# STM32H7P4xx register map
File version: 1.0
Registers are 32-bit, read-write, reset 0x0 unless marked. A register's access mark holds for its fields unless they carry their own. Offsets are from the block's base; [hi:lo] are bit positions.

## FDCAN1 — FD Controller Area Network (FDCAN)
Base 0x4000A000
Same registers: FDCAN2 0x4000A400, FDCAN3 0x4000A800
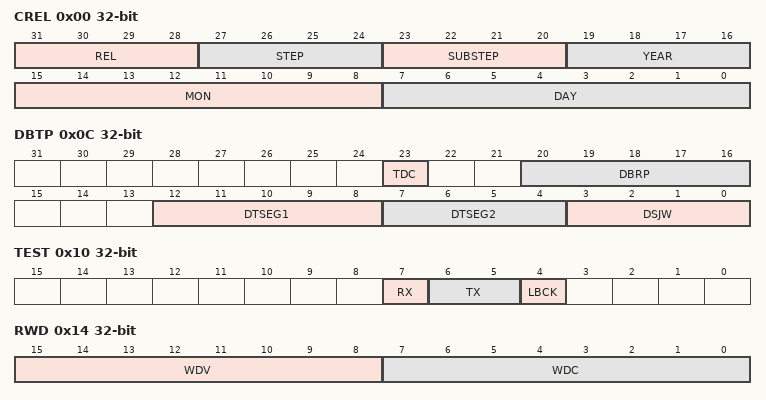
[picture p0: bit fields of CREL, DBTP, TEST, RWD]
0x00 CREL ro — FDCAN Core Release register
  [31:28] REL, [27:24] STEP, [23:20] SUBSTEP, [19:16] YEAR, [15:8] MON, [7:0] DAY
0x04 ENDN ro — FDCAN Endian register
  [31:0] ETV — Endianness test value
0x0C DBTP — FDCAN Data Bit Timing & Prescaler register
  [23] TDC — Transceiver delay compensation
  [20:16] DBRP — Data bit rate prescaler
  [12:8] DTSEG1 — Data time segment before sample point
  [7:4] DTSEG2 — Data time segment after sample point
  [3:0] DSJW — Synchronization jump width
0x10 TEST — FDCAN Test register
  [7] RX — Receive pin
  [6:5] TX — Control of transmit pin
  [4] LBCK — Loop back mode
0x14 RWD — FDCAN RAM Watchdog register
  [15:8] WDV — Watchdog value
  [7:0] WDC — Watchdog configuration
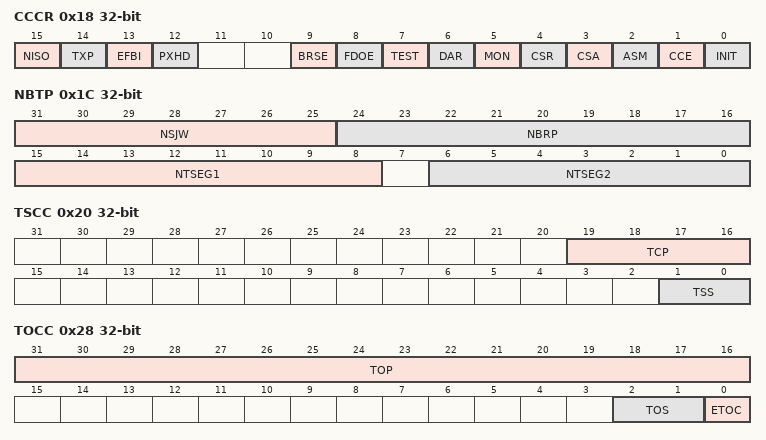
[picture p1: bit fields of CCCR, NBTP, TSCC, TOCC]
0x18 CCCR — FDCAN CC Control register
  [15] NISO — Non ISO operation
  [14] TXP — If this bit is set, the FDCAN pauses for two CAN bit times before starting the next transmission after successfully transmitting a frame
  [13] EFBI — Edge filtering during bus integration
  [12] PXHD — Protocol exception handling disable
  [9] BRSE — FDCAN bit rate switching
  [8] FDOE — FD operation enable
  [7] TEST — Test mode enable
  [6] DAR — Disable automatic retransmission
  [5] MON — Bus monitoring mode
  [4] CSR — Clock stop request
  [3] CSA — Clock stop acknowledge
  [2] ASM — ASM restricted operation mode
  [1] CCE — Configuration change enable
  [0] INIT — Initialization
0x1C NBTP — FDCAN Nominal Bit Timing & Prescaler register
  [31:25] NSJW — Nominal (re)synchronization jump width
  [24:16] NBRP — Bit rate prescaler
  [15:8] NTSEG1 — Nominal time segment before sample point
  [6:0] NTSEG2 — Nominal time segment after sample point
0x20 TSCC — FDCAN Timestamp Counter Configuration register
  [19:16] TCP — Timestamp counter prescaler
  [1:0] TSS — Timestamp select
0x24 TSCV — FDCAN Timestamp Counter Value register
  [15:0] TSC — Timestamp counter
0x28 TOCC — FDCAN Timeout Counter Configuration register
  [31:16] TOP — Timeout period
  [2:1] TOS — Timeout select
  [0] ETOC — Timeout counter enable
0x2C TOCV — FDCAN Timeout Counter Value register
  [15:0] TOC — Timeout counter
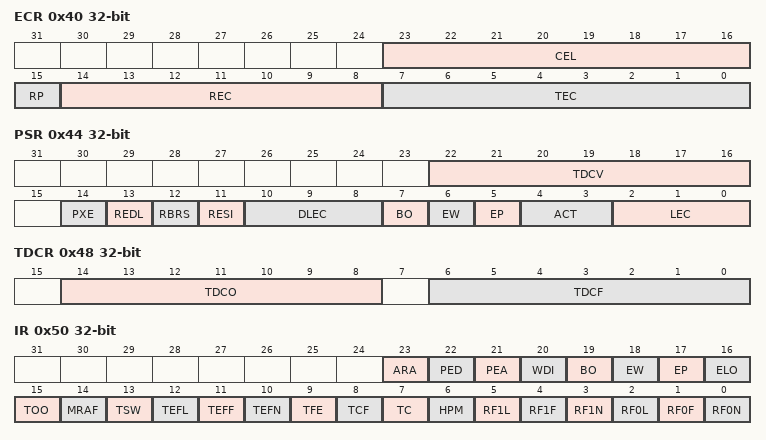
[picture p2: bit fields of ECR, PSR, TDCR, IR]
0x40 ECR ro — FDCAN Error Counter register
  [23:16] CEL — CAN error logging
  [15] RP — Receive error passive
  [14:8] REC — Receive error counter
  [7:0] TEC — Transmit error counter
0x44 PSR ro — FDCAN Protocol Status register
  [22:16] TDCV — Transmitter delay compensation value
  [14] PXE — Protocol exception event
  [13] REDL — Received FDCAN message
  [12] RBRS — BRS flag of last received FDCAN message
  [11] RESI — ESI flag of last received FDCAN message
  [10:8] DLEC — Data last error code
  [7] BO — Bus_Off status
  [6] EW — Warning Sstatus
  [5] EP — Error passive
  [4:3] ACT — Activity
  [2:0] LEC — Last error code
0x48 TDCR — FDCAN Transmitter Delay Compensation register
  [14:8] TDCO — Transmitter delay compensation offset
  [6:0] TDCF — Transmitter delay compensation filter window length
0x50 IR — FDCAN Interrupt register
  [23] ARA — Access to reserved address
  [22] PED — Protocol error in data phase (data bit time is used)
  [21] PEA — Protocol error in arbitration phase (nominal bit time is used)
  [20] WDI — Watchdog interrupt
  [19] BO — Bus_Off status
  [18] EW — Warning status
  [17] EP — Error passive
  [16] ELO — Error logging overflow
  [15] TOO — Timeout occurred
  [14] MRAF — Message RAM access failure
  [13] TSW — Timestamp wraparound
  [12] TEFL — Tx event FIFO element lost
  [11] TEFF — Tx event FIFO full
  [10] TEFN — Tx event FIFO New Entry
  [9] TFE — Tx FIFO empty
  [8] TCF — Transmission cancellation finished
  [7] TC — Transmission completed
  [6] HPM — High-priority message
  [5] RF1L — Rx FIFO 1 message lost
  [4] RF1F — Rx FIFO 1 full
  [3] RF1N — Rx FIFO 1 new message
  [2] RF0L — Rx FIFO 0 message lost
  [1] RF0F — Rx FIFO 0 full
  [0] RF0N — Rx FIFO 0 new message
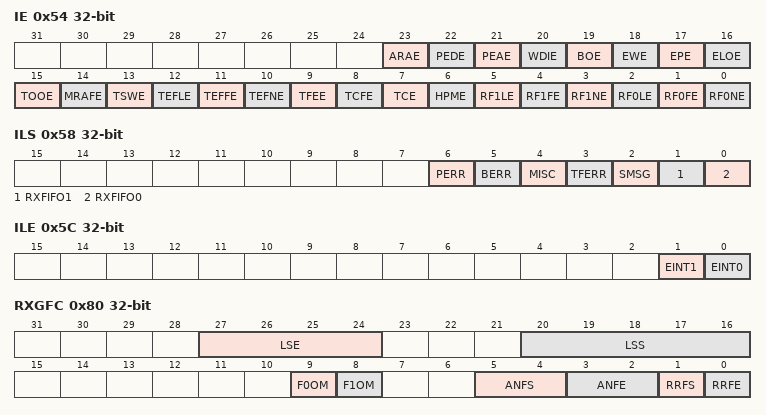
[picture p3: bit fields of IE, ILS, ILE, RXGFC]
0x54 IE — FDCAN Interrupt Enable register
  [23] ARAE — Access to reserved address enable
  [22] PEDE — Protocol error in data phase enable
  [21] PEAE — Protocol error in arbitration phase enable
  [20] WDIE — Watchdog interrupt enable
  [19] BOE — Bus_Off status
  [18] EWE — Warning status interrupt enable
  [17] EPE — Error passive interrupt enable
  [16] ELOE — Error logging overflow interrupt enable
  [15] TOOE — Timeout occurred interrupt enable
  [14] MRAFE — Message RAM access failure interrupt enable
  [13] TSWE — Timestamp wraparound interrupt enable
  [12] TEFLE — Tx event FIFO element lost interrupt enable
  [11] TEFFE — Tx event FIFO full interrupt enable
  [10] TEFNE — Tx event FIFO new entry interrupt enable
  [9] TFEE — Tx FIFO empty interrupt enable
  [8] TCFE — Transmission cancellation finished interrupt enable
  [7] TCE — Transmission completed interrupt enable
  [6] HPME — High-priority message interrupt enable
  [5] RF1LE — Rx FIFO 1 message lost interrupt enable
  [4] RF1FE — Rx FIFO 1 full interrupt enable
  [3] RF1NE — Rx FIFO 1 new message interrupt enable
  [2] RF0LE — Rx FIFO 0 message lost interrupt enable
  [1] RF0FE — Rx FIFO 0 full interrupt enable
  [0] RF0NE — Rx FIFO 0 new message interrupt enable
0x58 ILS — FDCAN Interrupt Line Select register
  [6] PERR — Protocol error grouping the following interruption
  [5] BERR — Bit and line error grouping the following interruption
  [4] MISC — Interrupt regrouping the following interruption
  [3] TFERR — Tx FIFO ERROR grouping the following interruption
  [2] SMSG — Status message bit grouping the following interruption
  [1] RXFIFO1 — RX FIFO bit grouping the following interruption
  [0] RXFIFO0 — RX FIFO bit grouping the following interruption
0x5C ILE — FDCAN Interrupt Line Enable register
  [1] EINT1 — Enable interrupt line 1
  [0] EINT0 — Enable interrupt line 0
0x80 RXGFC — FDCAN Global Filter Configuration register
  [27:24] LSE — List size extended
  [20:16] LSS — List size standard
  [9] F0OM — FIFO 0 operation mode (overwrite or blocking)
  [8] F1OM — FIFO 1 operation mode (overwrite or blocking)
  [5:4] ANFS — Accept Non-matching frames standard
  [3:2] ANFE — Accept non-matching frames extended
  [1] RRFS — Reject remote frames standard
  [0] RRFE — Reject remote frames extended
0x84 XIDAM — FDCAN Extended ID AND Mask register
  [28:0] EIDM — Extended ID mask
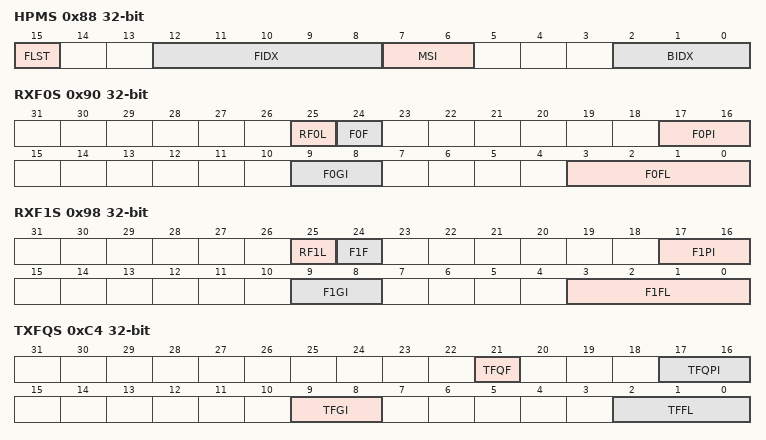
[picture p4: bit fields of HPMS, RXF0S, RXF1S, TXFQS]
0x88 HPMS ro — FDCAN High Priority Message Status register
  [15] FLST — Filter list
  [12:8] FIDX — Filter index
  [7:6] MSI — Message storage indicator
  [2:0] BIDX — Buffer index
0x90 RXF0S ro — FDCAN Rx FIFO 0 Status register
  [25] RF0L — Rx FIFO 0 message lost
  [24] F0F — Rx FIFO 0 full
  [17:16] F0PI — Rx FIFO 0 put index
  [9:8] F0GI — Rx FIFO 0 get index
  [3:0] F0FL — Rx FIFO 0 fill level
0x94 RXF0A — FDCAN Rx FIFO 0 Acknowledge register
  [2:0] F0AI — Rx FIFO 0 acknowledge index
0x98 RXF1S ro — FDCAN Rx FIFO 1 Status register
  [25] RF1L — Rx FIFO 1 message lost
  [24] F1F — Rx FIFO 1 full
  [17:16] F1PI — Rx FIFO 1 put index
  [9:8] F1GI — Rx FIFO 1 get index
  [3:0] F1FL — Rx FIFO 1 fill level
0x9C RXF1A — FDCAN Rx FIFO 1 Acknowledge register
  [2:0] F1AI — Rx FIFO 1 acknowledge index
0xC0 TXBC — FDCAN Tx Buffer Configuration register
  [24] TFQM — Tx FIFO/queue mode
0xC4 TXFQS ro — FDCAN Tx FIFO/Queue Status register
  [21] TFQF — Tx FIFO/queue full
  [17:16] TFQPI — Tx FIFO/queue put index
  [9:8] TFGI — Tx FIFO get index
  [2:0] TFFL — Tx FIFO free level
0xC8 TXBRP ro — FDCAN Tx Buffer Request Pending register
  [2:0] TRP — Transmission request pending
0xCC TXBAR — FDCAN Tx Buffer Add Request register
  [2:0] AR — Add request
0xD0 TXBCR — FDCAN Tx Buffer Cancellation Request register
  [2:0] CR — Cancellation request
0xD4 TXBTO ro — FDCAN Tx Buffer Transmission Occurred register
  [2:0] TO — Transmission occurred
0xD8 TXBCF ro — FDCAN Tx Buffer Cancellation Finished register
  [2:0] CF — Cancellation finished
0xDC TXBTIE — FDCAN Tx Buffer Transmission Interrupt Enable register
  [2:0] TIE — Transmission interrupt enable
0xE0 TXBCIE — FDCAN Tx Buffer Cancellation Finished Interrupt Enable register
  [2:0] CFIE — Cancellation finished interrupt enable
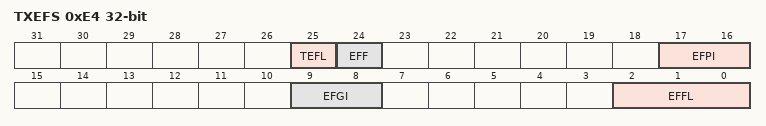
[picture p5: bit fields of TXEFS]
0xE4 TXEFS ro — FDCAN Tx Event FIFO Status register
  [25] TEFL — Tx event FIFO element lost
  [24] EFF — Event FIFO full
  [17:16] EFPI — Event FIFO put index
  [9:8] EFGI — Event FIFO get index
  [2:0] EFFL — Event FIFO fill level
0xE8 TXEFA — FDCAN Tx Event FIFO Acknowledge register
  [1:0] EFAI — Event FIFO acknowledge index
